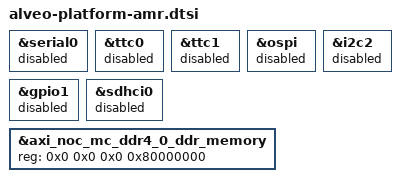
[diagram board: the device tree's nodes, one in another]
/*
 * SPDX-License-Identifier: GPL-2.0-only
 *
 * dtsi for ALveo V80 AMR platform
 *
 * Copyright (C) 2026, Advanced Micro Devices, Inc.  All rights reserved.
 *
 */

/* Workaround deleting the HBM memory nodes which is causing the kernel hangs */

/ {
        /delete-node/ memory@4000000000;
        /delete-node/ memory@60000000000;
};

&serial0 {
        status = "disabled";
};

&ttc0 {
        status = "disabled";
};

&ttc1 {
        status = "disabled";
};

&ospi {
        status = "disabled";
};

&i2c2 {
        status = "disabled";
};

&gpio1 {
        status = "disabled";
};

&sdhci0 {
        status = "disabled";
};

&axi_noc_mc_ddr4_0_ddr_memory {
        reg = <0x0 0x0 0x0 0x80000000>;
};
